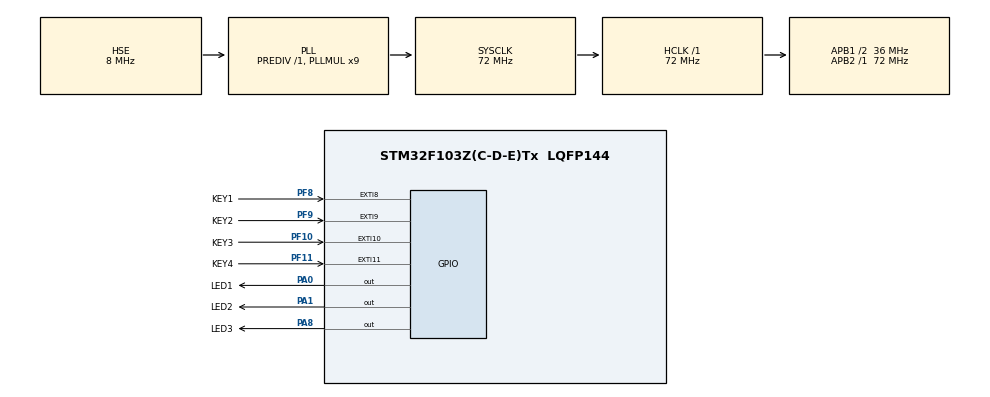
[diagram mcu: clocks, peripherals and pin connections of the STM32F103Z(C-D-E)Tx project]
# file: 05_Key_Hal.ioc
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Mcu.Family=STM32F1
Mcu.Name=STM32F103Z(C-D-E)Tx
Mcu.Package=LQFP144
NVIC.EXTI15_10_IRQn=true\:3\:0\:true\:false\:true\:true\:true\:true
NVIC.EXTI9_5_IRQn=true\:3\:0\:true\:false\:true\:true\:true\:true
NVIC.PriorityGroup=NVIC_PRIORITYGROUP_4
OSC_IN.Mode=HSE-External-Oscillator
OSC_IN.Signal=RCC_OSC_IN
OSC_OUT.Mode=HSE-External-Oscillator
OSC_OUT.Signal=RCC_OSC_OUT
PA0-WKUP.GPIO_Label=LED1
PA0-WKUP.GPIO_Speed=GPIO_SPEED_FREQ_HIGH
PA0-WKUP.PinState=GPIO_PIN_SET
PA0-WKUP.Signal=GPIO_Output
PA1.GPIO_Label=LED2
PA1.GPIO_Speed=GPIO_SPEED_FREQ_HIGH
PA1.PinState=GPIO_PIN_SET
PA1.Signal=GPIO_Output
PA13.Mode=Serial_Wire
PA13.Signal=SYS_JTMS-SWDIO
PA14.Mode=Serial_Wire
PA14.Signal=SYS_JTCK-SWCLK
PA8.GPIO_Label=LED3
PA8.GPIO_Speed=GPIO_SPEED_FREQ_HIGH
PA8.PinState=GPIO_PIN_SET
PA8.Signal=GPIO_Output
PC14-OSC32_IN.Mode=LSE-External-Oscillator
PC14-OSC32_IN.Signal=RCC_OSC32_IN
PC15-OSC32_OUT.Mode=LSE-External-Oscillator
PC15-OSC32_OUT.Signal=RCC_OSC32_OUT
PF10.GPIO_Label=KEY3
PF10.GPIO_PuPd=GPIO_PULLDOWN
PF10.Signal=GPXTI10
PF11.GPIO_Label=KEY4
PF11.GPIO_PuPd=GPIO_PULLDOWN
PF11.Signal=GPXTI11
PF8.GPIO_Label=KEY1
PF8.GPIO_ModeDefaultEXTI=GPIO_MODE_IT_FALLING
PF8.GPIO_PuPd=GPIO_PULLUP
PF8.Signal=GPXTI8
PF9.GPIO_Label=KEY2
PF9.GPIO_ModeDefaultEXTI=GPIO_MODE_IT_FALLING
PF9.GPIO_PuPd=GPIO_PULLUP
PF9.Signal=GPXTI9
ProjectManager.HeapSize=0x200
ProjectManager.StackSize=0x400
ProjectManager.TargetToolchain=MDK-ARM V5.32
RCC.AHBFreq_Value=72000000
RCC.APB1CLKDivider=RCC_HCLK_DIV2
RCC.APB1Freq_Value=36000000
RCC.APB1TimFreq_Value=72000000
RCC.APB2Freq_Value=72000000
RCC.APB2TimFreq_Value=72000000
RCC.HCLKFreq_Value=72000000
RCC.PLLMUL=RCC_PLL_MUL9
RCC.PLLSourceVirtual=RCC_PLLSOURCE_HSE
RCC.SYSCLKFreq_VALUE=72000000
RCC.SYSCLKSource=RCC_SYSCLKSOURCE_PLLCLK
RCC.USBFreq_Value=72000000
board=custom

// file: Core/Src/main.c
/* USER CODE BEGIN Header */
/**
  ******************************************************************************
  * @file           : main.c
  * @brief          : Main program body
  ******************************************************************************
  * @attention
  *
  * Copyright (c) 2024 STMicroelectronics.
  * All rights reserved.
  *
  * This software is licensed under terms that can be found in the LICENSE file
  * in the root directory of this software component.
  * If no LICENSE file comes with this software, it is provided AS-IS.
  *
  ******************************************************************************
  */
  /* USER CODE END Header */
  /* Includes ------------------------------------------------------------------*/
#include "main.h"
#include "gpio.h"

/* USER CODE BEGIN PV */
extern uint8_t flag;
/* USER CODE END PV */

void SystemClock_Config(void);

int main(void)
{

    /* MCU Configuration--------------------------------------------------------*/

    /* Reset of all peripherals, Initializes the Flash interface and the Systick. */
    HAL_Init();

    /* Configure the system clock */
    SystemClock_Config();

    /* Initialize all configured peripherals */
    MX_GPIO_Init();
    /* USER CODE BEGIN 2 */
    uint16_t leds[] = { LED1_Pin,LED2_Pin,LED3_Pin };
    GPIO_TypeDef* LedsPort[] = { LED1_GPIO_Port, LED2_GPIO_Port,LED3_GPIO_Port };
    /* USER CODE END 2 */

    /* Infinite loop */
    /* USER CODE BEGIN WHILE */
    while (1)
    {
        if (flag)
        {
            for (uint8_t i = 0; i < 3; i++)
            {
                HAL_GPIO_WritePin(LedsPort[i], leds[i], GPIO_PIN_RESET);
                HAL_Delay(200);
                HAL_GPIO_WritePin(LedsPort[i], leds[i], GPIO_PIN_SET);
            }
        }

        /* USER CODE END WHILE */

    }
}

void SystemClock_Config(void)
{
    RCC_OscInitTypeDef RCC_OscInitStruct = { 0 };
    RCC_ClkInitTypeDef RCC_ClkInitStruct = { 0 };

    /** Initializes the RCC Oscillators according to the specified parameters
    * in the RCC_OscInitTypeDef structure.
    */
    RCC_OscInitStruct.OscillatorType = RCC_OSCILLATORTYPE_HSE;
    RCC_OscInitStruct.HSEState = RCC_HSE_ON;
    RCC_OscInitStruct.HSEPredivValue = RCC_HSE_PREDIV_DIV1;
    RCC_OscInitStruct.HSIState = RCC_HSI_ON;
    RCC_OscInitStruct.PLL.PLLState = RCC_PLL_ON;
    RCC_OscInitStruct.PLL.PLLSource = RCC_PLLSOURCE_HSE;
    RCC_OscInitStruct.PLL.PLLMUL = RCC_PLL_MUL9;
    if (HAL_RCC_OscConfig(&RCC_OscInitStruct) != HAL_OK)
    {
        Error_Handler();
    }

    /** Initializes the CPU, AHB and APB buses clocks
    */
    RCC_ClkInitStruct.ClockType = RCC_CLOCKTYPE_HCLK | RCC_CLOCKTYPE_SYSCLK
        | RCC_CLOCKTYPE_PCLK1 | RCC_CLOCKTYPE_PCLK2;
    RCC_ClkInitStruct.SYSCLKSource = RCC_SYSCLKSOURCE_PLLCLK;
    RCC_ClkInitStruct.AHBCLKDivider = RCC_SYSCLK_DIV1;
    RCC_ClkInitStruct.APB1CLKDivider = RCC_HCLK_DIV2;
    RCC_ClkInitStruct.APB2CLKDivider = RCC_HCLK_DIV1;

    if (HAL_RCC_ClockConfig(&RCC_ClkInitStruct, FLASH_LATENCY_2) != HAL_OK)
    {
        Error_Handler();
    }
}

void Error_Handler(void)
{
    __disable_irq();
    while (1)
    {
    }
}
